# nrf5340 register map
Vendor: Nordic Semiconductor; Series: nrf53; File version: 1
CPU: CM33 r0p2, little endian, MPU, FPU, 3 interrupt priority bits
Registers are 32-bit, read-write, reset 0x0 unless marked. A register's access mark holds for its fields unless they carry their own. Offsets are from the block's base; [hi:lo] are bit positions; lines under a group give offsets from that group; 'fields as' and 'values as' point back to an identical list.

## REGULATORS_NS — Voltage regulators 0
Base 0x40004000; alternate view of OSCILLATORS_NS
Same registers: REGULATORS_S 0x50004000 (alternate view of OSCILLATORS_S)
0x428 MAINREGSTATUS ro — Main supply status
  [0] VREGH — VREGH status
    0=Inactive (Normal voltage mode. Voltage supplied on VDD.); 1=Active (High voltage mode. Voltage supplied on VDDH.)
0x434 DISABLEHPBOR wo — Enable or disable HPBOR
  [0] DISABLE
    0=Enabled (Enable HPBOR); 1=Disabled (Disable HPBOR)
0x500 SYSTEMOFF wo
  [0] SYSTEMOFF — Enable System OFF mode
    1=Enter (Enable System OFF mode)
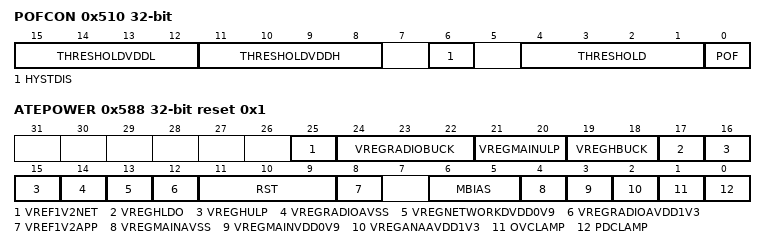
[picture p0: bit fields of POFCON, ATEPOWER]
0x510 POFCON — Power failure comparator configuration
  [15:12] THRESHOLDVDDL — Power failure comparator threshold setting for voltage supply on VDDL
    0=V100 (Set threshold to 1.0 V); 1=V105 (Set threshold to 1.05 V); 2=V110 (Set threshold to 1.10 V); 3=V115 (Set threshold to 1.15 V); 4=V120 (Set threshold to 1.20 V); 5=V125 (Set threshold to 1.25 V); 6=V130 (Set threshold to 1.30 V); 7=V135 (Set threshold to 1.35 V); 8=V140 (Set threshold to 1.40 V); 9=V145 (Set threshold to 1.45 V); 10=V150 (Set threshold to 1.50 V); 11=V155 (Set threshold to 1.55 V); 12=V160 (Set threshold to 1.60 V); 13=V165 (Set threshold to 1.65 V); 14=V170 (Set threshold to 1.70 V); 15=V175 (Set threshold to 1.75 V)
  [11:8] THRESHOLDVDDH — Power failure comparator threshold setting for voltage supply on VDDH
    0=V27 (Set threshold to 2.7 V); 1=V28 (Set threshold to 2.8 V); 2=V29 (Set threshold to 2.9 V); 3=V30 (Set threshold to 3.0 V); 4=V31 (Set threshold to 3.1 V); 5=V32 (Set threshold to 3.2 V); 6=V33 (Set threshold to 3.3 V); 7=V34 (Set threshold to 3.4 V); 8=V35 (Set threshold to 3.5 V); 9=V36 (Set threshold to 3.6 V); 10=V37 (Set threshold to 3.7 V); 11=V38 (Set threshold to 3.8 V); 12=V39 (Set threshold to 3.9 V); 13=V40 (Set threshold to 4.0 V); 14=V41 (Set threshold to 4.1 V); 15=V42 (Set threshold to 4.2 V)
  [6] HYSTDIS — Bypass power failure comparator hysteresis
    0=Normal (Hysteresis active); 1=NoHyst (Hysteresis disabled)
  [4:1] THRESHOLD — Power failure comparator threshold setting
    4=V17 (Set threshold to 1.7 V); 5=V18 (Set threshold to 1.8 V); 6=V19 (Set threshold to 1.9 V); 7=V20 (Set threshold to 2.0 V); 8=V21 (Set threshold to 2.1 V); 9=V22 (Set threshold to 2.2 V); 10=V23 (Set threshold to 2.3 V); 11=V24 (Set threshold to 2.4 V); 12=V25 (Set threshold to 2.5 V); 13=V26 (Set threshold to 2.6 V); 14=V27 (Set threshold to 2.7 V); 15=V28 (Set threshold to 2.8 V)
  [0] POF — Enable or disable power failure comparator
    0=Disabled; 1=Enabled
0x514 IGNOREDAPCPWRREGMODE wo — Ignore DAPCP power mode
  [0] IGNOREDAPCPWRREGMODE — Ignore power request from debugger
    0=Do not ignore power request form debugger; 1=Ignore power request from debugger
0x518 RSTVTHTRIM — Threshold trim, power on reset
  [4:0] RSTVTHTRIM
0x51C BORLVBATTTRIM — Threshold trim, brown-out reset for VDDL battery
  [3:0] BORLVBATTTRIM
0x520 BGREFTRIM — Master bias bandgap trim
  [3:0] BGREFTRIM — Threshold trim, brown-out reset for VDDL battery
0x548 FORCEOFFNVM — Force off NVM supply. See also the internal section in the NVMC chapter.
  [31:0] FORCEOFFNVM
    on read: 0=DoNotForceOff (Read: Do not force off NVM supply.); 1=ForceOff (Read: Force off NVM supply.) | on write: 0=DisableForceOff (Write: Do not force off NVM supply.); 0xBADCA81E=EnableForceOff (Write: Force off NVM supply.)
0x588 ATEPOWER reset 0x1 — Analog test bus control for power modules
  [25] VREF1V2NET — Connect or disconnect reference generator for Network flash to analog test bus
    0=Disconnected; 1=Connected (Connect 0.9 V downscaled reference voltage to ATB0)
  [24:22] VREGRADIOBUCK — Connect or disconnect TBD to analog test bus
  [21:20] VREGMAINULP — Connect or disconnect TBD to analog test bus
    0=Disconnected; 1=Connected (Connect to ATB1)
  [19:18] VREGHBUCK — Connect or disconnect VREGRADIO DVDD0V9 to analog test bus
    0=Disconnected; 1=Connected (Connect to ATB1)
  [17] VREGHLDO — Connect or disconnect TBD to analog test bus
    0=Disconnected; 1=Connected (Connect to ATB1)
  [16:15] VREGHULP — Connect or disconnect TBD to analog test bus
    0=Disconnected; 1=Connected (Connect to ATB1)
  [14] VREGRADIOAVSS — Connect or disconnect VREGRADIO AVDDSS to analog test bus
    0=Disconnected; 1=Connected (Connect to ATB1)
  [13] VREGNETWORKDVDD0V9 — Connect or disconnect VREGRADIO DVDD0V9 to analog test bus
    0=Disconnected; 1=Connected (Connect to ATB1)
  [12] VREGRADIOAVDD1V3 — Connect or disconnect VREGRADIO AVDD1V3 to analog test bus
    0=Disconnected; 1=Connected (Connect to ATB1)
  [11:9] RST — Test signals for the RST analog cell
  [8] VREF1V2APP — Connect or disconnect reference generator for Application flash to analog test bus
    values as VREF1V2NET
  [6:5] MBIAS — Configure connection of master bias generator to analog test bus
    0=Disconnected; 1=VBG (Connect 0.9 V bandgap voltage to ATB0); 2=IBPSR10U (Connect 10 uA IBPSR current to ATB1); 3=Both (Connect both VBG to ATB0 and IBPSR10U to ATB1)
  [4] VREGMAINAVSS — Connect or disconnect VREGMAIN AVSS to analog test bus
    0=Disconnected; 1=Connected (Connect to ATB1)
  [3] VREGMAINVDD0V9 — Connect or disconnect VREGMAIN DVDD_0V9 to analog test bus
    0=Disconnected; 1=Connected (Connect to ATB0)
  [2] VREGANAAVDD1V3 — Connect or disconnect VREGANA AVDD_1V3 to analog test bus
    0=Disconnected; 1=Connected (Connect to ATB0)
  [1] OVCLAMP — Enable or disable overvoltage clamp on analog test bus
    0=Disabled; 1=Enabled
  [0] PDCLAMP — Enable or disable power-down clamp on analog test bus
    0=Disabled; 1=Enabled
0x700 VREGMAIN group — Unspecified
  0x00 VOUT — Control the output voltage for DVDD_1V3
    [1:0] VOUT — Output voltage
      0=1.0 V; 1=1.09 V; 2=1.17 V (default) - should be adjusted to 1.20; 3=1.26 V
  0x04 DCDCEN — DC/DC enable register for main regulator.
    [0] DCDCEN — Enable or disable DC/DC converter
      0=Disabled; 1=Enabled
  0x08 FORCEREGMODE — 3-bit backdoor register for manual selection of power mode
    [2:0] FORCEREGMODE — Force Regulator Mode to value
      0=EXT (Force external (DVDD_0V9 supplied externally)); 1=ULP (Force ULP mode); 2=LDO (Force LDO mode); 3=DCDC (Force DCDC mode); 4=DCDC_REFRESH (Force DCDC REFRESH mode)
  0x0C PWRREGTHRESHOLD — Set threshold value of power regulator
    [6:0] PWRREGTHRESHOLD — Sets the threshold value of power regulator.
  0x10 ENFORCEPWRREGMODE — Enable forcing of power mode in power regulator
    [0] ENFORCEPWRREGMODE
      0=Disabled (Pwr regulator forcing off); 1=Enabled (Pwr regulator mode forced to value given by FORCEREGMODE)
  0x14 CURRENTPWRREGMODE ro — Current mode in the power regulator
    [3:0] CURRENTPWRREGMODE
  0x18 DISABLEHSLIMIT
    [0] DISABLE — Enable or disable HSLIMIT for DCDC regulator
      0=Enabled (Enable HSLIMIT); 1=Disabled (Disable HSLIMIT)
  0x1C LDOTESTLOAD — Test load setting for VREGMAIN
    [2:0] VREGLOAD — Output load configuration (for test purposes)
      0=Normal operation (default); 1=1mATestLoad; 2=50mATestLoad; 3=150mATestLoad
  0x20 LDOCAL — Calibration register for the VREGMAIN LDO regulator.
    [2:0] VREGTRIM — Output voltage calibration.
      3=1.163 V; 2=1.136 V; 1=1.108 V; 0=1.082 V; 7=1.054 V; 6=1.029 V; 5=1.003 V; 4=0.980 V
  0x28 VREGHIGH — Increase voltage to AVDD_1V3 levels for VREGMAIN LDO regulator
    [0] ENABLE — Enable or disable the feature
      0=Disabled (Nominal output levels of VREGMAIN LDO); 1=Enabled (Increased output levels of VREGMAIN LDO)
  0x30 BUCKCAL — Calibration register for VREGMAIN DCDC regulator.
    [4:0] BUCK_CAL — Output voltage calibration. 0: Minimum output voltage level. 31: Maximum output voltage level.
  0x34 BUCKCKSEL — Input clock selection for VREGMAIN DCDC regulator.
    [1:0] BUCKCKSEL — Input clock selection.
      0=NORMAL (normal clock); 1=INVERTED (inverted clock)
  0x38 BUCKDROUTSEL — Pre-driver speed control
    [3:0] BUCKDROUTSEL — 0: Minimum driver speed, low efficiency, low noise. 7: Medium driver speed, medium efficiency, medium noise. 15: Maximum driver speed, high efficiency, high noise.
  0x3C ULPDVDDSELREF — Select DVDD0V9 reference
    [1:0] ULPDVDDSELREF — Output voltage calibration. 0: 0.75V ratio of AVDD1V3 output (default) 1: 0.75V reference 2: AVDD1V3 as reference. 3: Reserved for future use.
  0x40 ULPRESCTRL — Switched resistor control
    [1:0] ULPRESCTRL — Output voltage calibration. 0: switched with internal oscillator (default). 1: switched with CLK2K input 2: force always on. 3: force off (PWRUPs must be 0 otherwise default).
  0x44 ULPICTRL — Adjusts current in reference (production calibrated)
    [3:0] ULPICTRL — 0: minimum current. 7: default. 15: maximum current.
  0x48 VCORECTRL — Spare digital signals
    [1:0] VCORECTRL
  0x4C VCORECALIBVCO — Internal oscillator calibration word
    [4:0] VCORECALIBVCO — 0: Low output frequency. 15: Default output frequency. 31: High output frequency.
0x800 VREGANA group — Unspecified
  0x00 FORCEREGMODE — 3-bit backdoor register for manual selection of power mode
    [2:0] FORCEREGMODE — Force Regulator Mode to value
      0=EXT (Force external (DVDD_0V9 supplied externally)); 1=ULP (Force ULP mode); 2=LDO (Force LDO mode)
  0x04 ENFORCEPWRREGMODE — Enable forcing of power mode in power regulator
    fields as VREGMAIN.ENFORCEPWRREGMODE
  0x08 CURRENTPWRREGMODE ro — Current mode in the power regulator
    [3:0] CURRENTPWRREGMODE
  0x0C DISABLEHSLIMIT
    [0] DISABLE — Enable or disable HSLIMIT
      0=Enabled (Enable HSLIMIT); 1=Disabled (Disable HSLIMIT)
  0x10 LDOTESTLOAD — Test load setting for VREGANA.
    fields as VREGMAIN.LDOTESTLOAD
  0x14 LDOCAL — Configuration register for the VREGANA LDO regulator.
    [2:0] VREGTRIM — Output voltage calibration.
      3=1.357 V; 2=1.324 V; 1=1.289 V; 0=1.255 V; 7=1.219 V; 6=1.185 V; 5=1.150 V; 4=1.170 V
  0x18 ULPCAL — Calibration register for VREGANA ULP regulator .
    [4:0] ULPTRIM — Output voltage calibration. 0: minimum voltage 31: maximum voltage
0x900 VREGRADIO group — Unspecified
  0x00 VOUT — Control the output voltage for RVDD_1V3 Note: This is overridden by VOUTREQH when VREQH is requested by the network MCU.
    [1:0] VOUT — Output voltage
      0=1.0 V; 1=1.09 V; 2=1.18 V; 3=1.27 V
  0x04 DCDCEN — DC/DC enable register for VREGRADIO
    fields as VREGMAIN.DCDCEN
  0x08 ENFORCEPWRREGMODE — Enable forcing of power mode in power regulator
    fields as VREGMAIN.ENFORCEPWRREGMODE
  0x0C FORCEREGMODE — 3-bit backdoor register for manual selection of power mode
    [2:0] FORCEREGMODE — Force Regulator Mode to value
      0=Ext (Forceo external); 1=ULP (Force ULP mode); 2=LDO (Force LDO mode); 3=DCDC (Force DCDC mode); 4=REF (Force REF mode)
  0x10 CURRENTPWRREGMODE ro — Current mode in the power regulator
    [3:0] CURRENTPWRREGMODE
      0=Ext (External); 2=DCDC; 3=REF; 4=LDO (ULP DCDC); 6=LDO_DCDC; 7=LDO_REF; 8=ULP; 10=DCDC_ULP (ULP DCDC); 11=REF_ULP; 12=ULP_LDO (ULP DCDC)
  0x14 TESTLOAD — Test load setting for VREGRADIO.
    [2:0] TESTLOAD — Output load configuration (for test purposes)
      0=Normal operation (default); 1=1mATestLoad; 2=20mATestLoad
  0x18 ULPCAL — Calibration VREGRADIO ULP regulator
    [3:0] CAL — Calibration value
  0x1C DEBUG — Debug register - Control spare signals in POWER_LVLP
    [13:0] DEBUG — Connected to POWER_LVLP_DEBUG_0V9[12:0]
  0x20 VOUTREQH — Control the output voltage for RVDD_1V3 when VREQH is asserted. VREQH can be asserted through the network MCU.
    fields as VREGRADIO.VOUT
  0x24 BUCKCALMAXILIM
    [1:0] CALMAXILIM
  0x28 BUCKCALPWM
    [4:0] CALPWM
  0x2C BUCKPFMEN — PFM enable register for VREGRADIO regulator
    [0] PFMEN — Enable or disable PFM in VREGRADIO regulator
      0=Disabled (Disable PFM (default)); 1=Enabled (Enable PFM)
  0x30 BUCKPFMCAL
    [3:0] PFMCAL
  0x34 BUCKPFMICMPCAL
    [2:0] PFMICMPCAL
  0x38 BUCKPFMICMPCOUNT
    [15:0] PFMICMPCOUNT
  0x3C PWRREGTHRESHOLD — Set threshold value of power regulator
    [6:0] PWRREGTHRESHOLD — Sets the threshold value of power regulator.
0xA00 VREGNETWORK group — Unspecified
  0x00 VOUT — Control the output voltage for DVDD_0V9
    [3:0] VOUT — Output voltage
  0x04 ULPALWAYSON reset 0x1 — Keep DVDD_0V9 ULP regulator on at all times
    [0] ULPALWAYSON
      0=Disabled (DVDD_0V9 ULP regulator turned off in LDO modes); 1=Enabled (DVDD_0V9 ULP regulator always on)
  0x08 ENFORCEPWRREGMODE — Enable forcing of power mode in power regulator
    fields as VREGMAIN.ENFORCEPWRREGMODE
  0x0C FORCEREGMODE — 3-bit backdoor register for manual selection of power mode
    fields as VREGRADIO.FORCEREGMODE
  0x10 CURRENTPWRREGMODE ro — Current mode in the power regulator
    fields as VREGRADIO.CURRENTPWRREGMODE
  0x14 PWRREGICMPTIMER — Control the stay-alive time for the VREGNETWORK current comparator
    [15:0] COUNT
  0x18 TESTLOAD — Test load setting for VREGNETWORK.
    fields as VREGRADIO.TESTLOAD
  0x20 ULPCAL — Calibration VREGNETWORK ULP regulator
    [3:0] CAL — Calibration value
  0x24 ULPICMPCAL — Calibration of current comparator on DVDD_0V9 ULP regulator
    [2:0] CAL
  0x28 BYPASS — Bypass control for VREGNETWORK
    [0] CAL — Bypass control
      0=NormalMode (Normal operation (default)); 1=BypassMode (Output voltage is 30mV lower than input voltage)
0xC00 VREGH group — Unspecified
  0x00 DCDCEN — DC/DC enable register for VREGH.
    fields as VREGMAIN.DCDCEN
  0x04 BUCKCAL — BUCK_VIO output voltage fine calibration
    [4:0] BUCKCAL — BUCK_VIO output voltage fine calibration - connected to BUCKVIO_CAL_0V9[4:0]
  0x08 ULPICMPTRIM — Trimming of VREG_VIO_ULP load current measurement
    [1:0] ULPICMPTRIM
      0=m30pcnt (-30 percent); 1=m10pcnt (-10 percent (default)); 2=p10pcnt (+10 percent); 3=p30pcnt (+30 percent)
  0x0C VREGICMPTRIM — Trimming of VREG_VIO load current measurement
    [1:0] VREGICMPTRIM
      values as VREGH.ULPICMPTRIM.ULPICMPTRIM
  0x10 BUCKCALILIM — BUCK_VIO output current limit calibration
    [1:0] BUCKCALILIM
      0=65mA (default); 1=m20pcnt (-20 percent); 2=p40pcnt (+40 percent); 3=p20pcnt (+20 percent)
  0x14 EXTSUPPLY reset 0x1 — Enable external circuitry to be supplied from VDD pin).
    [0] EXTSUPPLY — Shadow register for corresponding register in UICR. Enable external circuitry to be supplied from VDD pin (output of REG0 stage). Applicable in 'High voltage mode' only.
      0=Disabled (No current can be drawn from the VDD pin.); 1=Enabled (It is allowed to supply external circuitry from the VDD pin.)
  0x18 RFSHBUCKCAL — Refresh mode trim register
    [1:0] RFSHBUCKCAL
  0x1C RFSHTRIMULP — Trimmed value for refresh mode counter for automatic mode change to ULP
    [5:0] RFSHTRIMULP
  0x20 RFSHTRIMPWM — Trimmed value for refresh mode counter for automatic mode change to PWM
    [5:0] RFSHTRIMPWM
  0x24 RFSHPOLLSEL — Programmable value for counter for poller in PWM mode
    [1:0] RFSHPOLLSEL
      0=256 us polling interval; 1=512 us polling interval; 2=1024 us polling interval; 3=Disabled
  0x28 BUCKCKDIV2 — Sets BUCK_VIO switching frequency
    [0] BUCKCKDIV2
      0=8MHz; 1=4MHz
  0x2C POWERCFG — Spare configuration signals for POWER_VIO
    [7:0] POWERCFG
  0x30 LDO2ULPOVERLAPTRIM — Programmable value for VREGH ldo to ulp overlay counter
    [0] LDO2ULPOVERLAPTRIM — Programmable value for VREGH LDO to ULP overlay counter. Value loaded from FICR->CHIPCONF06.LDOTOULPOVERLAPTRIM
      0=512 us overlay; 1=1024 us overlay
  0x34 ULPDISABLE — VREGH ULP mode
    [0] ULPDISABLE
      0=Auto (ULP mode is allowed); 1=Disabled (ULP mode is not allowed)
  0x38 CURRENTPWRREGMODE ro — Current mode in the VREGH power regulator
    [3:0] CURRENTPWRREGMODE
  0x3C VDDHDETECTED ro — Vddh is detected
    [0] VDDHDETECTED
      0=NotPresent (Vddh not detected); 1=Present (Vddh detected)
  0x40 EXTSILENTEN — Enable 'silent' external DCDC supply. This register only applies when DCDC is enabled in the VREGHDCDCEN register. Entering 'silent mode' forbids the use of DCDC refresh mode internally in VREGH.
    [0] EXTSILENTEN — Enable 'silent' external DCDC supply.
      0=Disabled; 1=Enabled
  0x44 ENFORCEPWRREGMODE — Enable forcing of power mode in power regulator
    fields as VREGMAIN.ENFORCEPWRREGMODE
  0x48 FORCEREGMODE — Force a specific power mode for VREGH
    [7:0] FORCEPWRREGMODE — Force a specific power mode
  0x4C PWRREGTHRESHOLD — Set threshold value of power regulator
    [6:0] PWRREGTHRESHOLD — Sets the threshold value of power regulator.
0xEE4 DISABLEPACSYSTEMOFFACK wo — Enable or disable System OFF ack from PAC
  [0] DISABLE
    0=Enabled (Enable ack); 1=Disabled (Disable ack)
0xEE8 DISABLESRAMSYSTEMOFFACK wo — Enable or disable System OFF ack from SRAM
  [0] DISABLE
    0=Enabled (Enable ack); 1=Disabled (Disable ack)
0xEEC DISABLENVMSYSTEMOFFACK wo — Enable or disable System OFF ack from NVM
  [0] DISABLE
    0=Enabled (Enable ack); 1=Disabled (Disable ack)
